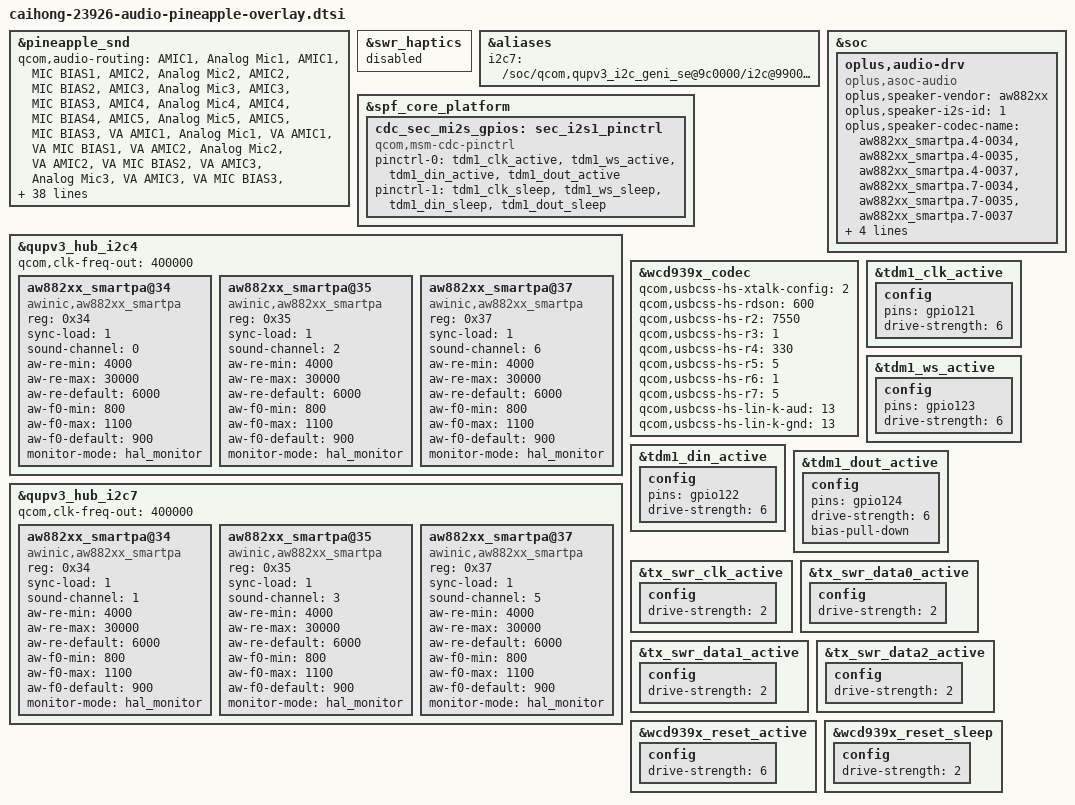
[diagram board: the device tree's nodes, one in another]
&pineapple_snd {
	qcom,audio-routing =
		"AMIC1", "Analog Mic1",
		"AMIC1", "MIC BIAS1",
		"AMIC2", "Analog Mic2",
		"AMIC2", "MIC BIAS2",
		"AMIC3", "Analog Mic3",
		"AMIC3", "MIC BIAS3",
		"AMIC4", "Analog Mic4",
		"AMIC4", "MIC BIAS4",
		"AMIC5", "Analog Mic5",
		"AMIC5", "MIC BIAS3",
		"VA AMIC1", "Analog Mic1",
		"VA AMIC1", "VA MIC BIAS1",
		"VA AMIC2", "Analog Mic2",
		"VA AMIC2", "VA MIC BIAS2",
		"VA AMIC3", "Analog Mic3",
		"VA AMIC3", "VA MIC BIAS3",
		"VA AMIC4", "Analog Mic4",
		"VA AMIC4", "VA MIC BIAS4",
		"VA AMIC5", "Analog Mic5",
		"VA AMIC5", "VA MIC BIAS3",
		"TX DMIC0", "Digital Mic0",
		"TX DMIC0", "MIC BIAS3",
		"TX DMIC1", "Digital Mic1",
		"TX DMIC1", "MIC BIAS3",
		"TX DMIC2", "Digital Mic2",
		"TX DMIC2", "MIC BIAS1",
		"TX DMIC3", "Digital Mic3",
		"TX DMIC3", "MIC BIAS1",
		"IN1_HPHL", "HPHL_OUT",
		"IN2_HPHR", "HPHR_OUT",
		"IN3_EAR", "AUX_OUT",
		"RX_TX DEC0_INP", "TX DEC0 MUX",
		"RX_TX DEC1_INP", "TX DEC1 MUX",
		"RX_TX DEC2_INP", "TX DEC2 MUX",
		"RX_TX DEC3_INP", "TX DEC3 MUX",
		"TX SWR_INPUT", "WCD_TX_OUTPUT",
		"VA SWR_INPUT", "VA_SWR_CLK",
		"VA SWR_INPUT", "WCD_TX_OUTPUT",
		"VA_AIF1 CAP", "VA_SWR_CLK",
		"VA_AIF2 CAP", "VA_SWR_CLK",
		"VA_AIF3 CAP", "VA_SWR_CLK",
		"VA DMIC0", "Digital Mic0",
		"VA DMIC1", "Digital Mic1",
		"VA DMIC2", "Digital Mic2",
		"VA DMIC3", "Digital Mic3",
		"VA DMIC0", "VA MIC BIAS3",
		"VA DMIC1", "VA MIC BIAS3",
		"VA DMIC2", "VA MIC BIAS1",
		"VA DMIC3", "VA MIC BIAS1";

	qcom,mi2s-audio-intf = <0>;
	qcom,tdm-audio-intf = <1>;
	qcom,tdm-max-slots = <8>;
	qcom,sec-mi2s-gpios = <&cdc_sec_mi2s_gpios>;

	qcom,msm-mbhc-usbc-audio-supported = <1>;
	qcom,msm-mbhc-hs-mic-max-threshold-mv = <2600>;
	qcom,msm-mbhc-hs-mic-min-threshold-mv = <112>; /* 75*2700/1800 */
	qcom,msm-mbhc-hphl-swh = <0>;
	qcom,msm-mbhc-gnd-swh = <0>;
	oplus,mbhc-headset-micbias-alwayon = <1>;
	oplus,mbhc-check-cross-conn = <1>;
	asoc-codec  = <&stub_codec>, <&lpass_cdc>,
		      <&wcd939x_codec>;
	asoc-codec-names = "msm-stub-codec.1", "lpass-cdc",
			   "wcd939x_codec";
	qcom,wsa-max-devs = <0>;
	qcom,wcd-disable-legacy-surge;
};

&swr_haptics {
	status = "disabled";
};

&aliases {
	i2c7 = "/soc/qcom,qupv3_i2c_geni_se@9c0000/i2c@990000";
};

&spf_core_platform {
	cdc_sec_mi2s_gpios: sec_i2s1_pinctrl {
		status = "ok";
		compatible = "qcom,msm-cdc-pinctrl";
		pinctrl-names = "aud_active", "aud_sleep";
		pinctrl-0 = <&tdm1_clk_active &tdm1_ws_active
				&tdm1_din_active &tdm1_dout_active>;
		pinctrl-1 = <&tdm1_clk_sleep &tdm1_ws_sleep
				&tdm1_din_sleep &tdm1_dout_sleep>;
		#gpio-cells = <0>;
	};
};

&qupv3_hub_i2c4 {
	status = "ok";
	qcom,clk-freq-out = <400000>;
	 /* AWINIC AW882XX mono Smart PA */
	 aw882xx_smartpa@34 {
		 compatible = "awinic,aw882xx_smartpa";
		 reg = <0x34>;
		 sync-load = <1>;
		 sound-channel = <0>;
		 aw-re-min = <4000>;
		 aw-re-max = <30000>;
		 aw-re-default = <6000>;
		 aw-f0-min = <800>;
		 aw-f0-max = <1100>;
		 aw-f0-default = <900>;
		 //aw-cali-mode = "none";
		 monitor-mode = "hal_monitor";
		 status = "okay";
	 };
	 aw882xx_smartpa@35 {
		 compatible = "awinic,aw882xx_smartpa";
		 reg = <0x35>;
		 sync-load = <1>;
		 sound-channel = <2>;
		 aw-re-min = <4000>;
		 aw-re-max = <30000>;
		 aw-re-default = <6000>;
		 aw-f0-min = <800>;
		 aw-f0-max = <1100>;
		 aw-f0-default = <900>;
		 //aw-cali-mode = "none";
		 monitor-mode = "hal_monitor";
		 status = "okay";
	 };
	 aw882xx_smartpa@37 {
		 compatible = "awinic,aw882xx_smartpa";
		 reg = <0x37>;
		 sync-load = <1>;
		 sound-channel = <6>;
		 aw-re-min = <4000>;
		 aw-re-max = <30000>;
		 aw-re-default = <6000>;
		 aw-f0-min = <800>;
		 aw-f0-max = <1100>;
		 aw-f0-default = <900>;
		 //aw-cali-mode = "none";
		 monitor-mode = "hal_monitor";
		 status = "okay";
	 };
};


&qupv3_hub_i2c7 {
	status = "ok";
	qcom,clk-freq-out = <400000>;
	 /* AWINIC AW882XX mono Smart PA */
	 aw882xx_smartpa@34 {
		 compatible = "awinic,aw882xx_smartpa";
		 reg = <0x34>;
		 sync-load = <1>;
		 sound-channel = <1>;
		 aw-re-min = <4000>;
		 aw-re-max = <30000>;
		 aw-re-default = <6000>;
		 aw-f0-min = <800>;
		 aw-f0-max = <1100>;
		 aw-f0-default = <900>;
		 //aw-cali-mode = "none";
		 monitor-mode = "hal_monitor";
		 status = "okay";
	 };
	 aw882xx_smartpa@35 {
		 compatible = "awinic,aw882xx_smartpa";
		 reg = <0x35>;
		 sync-load = <1>;
		 sound-channel = <3>;
		 aw-re-min = <4000>;
		 aw-re-max = <30000>;
		 aw-re-default = <6000>;
		 aw-f0-min = <800>;
		 aw-f0-max = <1100>;
		 aw-f0-default = <900>;
		 //aw-cali-mode = "none";
		 monitor-mode = "hal_monitor";
		 status = "okay";
	 };
	 aw882xx_smartpa@37 {
		 compatible = "awinic,aw882xx_smartpa";
		 reg = <0x37>;
		 sync-load = <1>;
		 sound-channel = <5>;
		 aw-re-min = <4000>;
		 aw-re-max = <30000>;
		 aw-re-default = <6000>;
		 aw-f0-min = <800>;
		 aw-f0-max = <1100>;
		 aw-f0-default = <900>;
		 //aw-cali-mode = "none";
		 monitor-mode = "hal_monitor";
		 status = "okay";
	 };
};

&soc {
	oplus,audio-drv {
		compatible = "oplus,asoc-audio";
		//for awinic speaker
		oplus,speaker-vendor = "aw882xx";
		oplus,speaker-i2s-id = <1>; 
		oplus,speaker-codec-name = "aw882xx_smartpa.4-0034", "aw882xx_smartpa.4-0035", "aw882xx_smartpa.4-0037","aw882xx_smartpa.7-0034", "aw882xx_smartpa.7-0035", "aw882xx_smartpa.7-0037";
		oplus,speaker-codec-dai-name = "aw882xx-aif-4-34", "aw882xx-aif-4-35", "aw882xx-aif-4-37","aw882xx-aif-7-34", "aw882xx-aif-7-35", "aw882xx-aif-7-37";
	};
};

&wcd939x_codec {
	/* 0 for digital crosstalk disabled,
	 * 1 for digital crosstalk with local sensed a-xtalk enabled, and
	 * 2 for digital crosstalk with remote sensed a-xtalk enabled.
	 */
	qcom,usbcss-hs-xtalk-config = <2>;
	qcom,usbcss-hs-rdson = <600>;
	qcom,usbcss-hs-r2 = <7550>;
	qcom,usbcss-hs-r3 = <1>;
	qcom,usbcss-hs-r4 = <330>;
	qcom,usbcss-hs-r5 = <5>;
	qcom,usbcss-hs-r6 = <1>;
	qcom,usbcss-hs-r7 = <5>;
	qcom,usbcss-hs-lin-k-aud = <13>;
	qcom,usbcss-hs-lin-k-gnd = <13>;
};

&tdm1_clk_active {
	config {
		pins = "gpio121";
		drive-strength = <6>;
	};
};

&tdm1_ws_active {
	config {
		pins = "gpio123";
		drive-strength = <6>;
	};
};

&tdm1_din_active {
	config {
		pins = "gpio122";
		drive-strength = <6>;
	};
};

&tdm1_dout_active {
	config {
		pins = "gpio124";
		drive-strength = <6>;
		bias-pull-down;
	};
};

&tx_swr_clk_active {
	config {
		drive-strength = <2>;   /* 2 mA */
	};
};

&tx_swr_data0_active {
	config {
		drive-strength = <2>;   /* 2 mA */
	};
};

&tx_swr_data1_active {
	config {
		drive-strength = <2>;   /* 2 mA */
	};
};

&tx_swr_data2_active {
	config {
		drive-strength = <2>;   /* 2 mA */
	};
};
&wcd939x_reset_active {
	config {
		drive-strength = <6>;   /* 6 mA */
	};
};
&wcd939x_reset_sleep {
	config {
		drive-strength = <2>;   /* 2 mA */
	};
};
